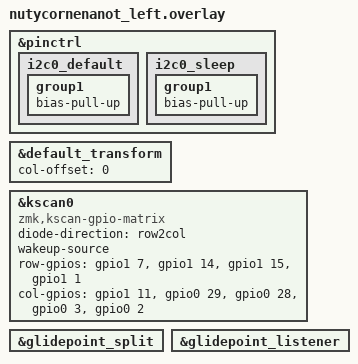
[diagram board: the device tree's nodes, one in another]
#include <input/processors.dtsi>  
#include <dt-bindings/zmk/input_transform.h>
#include <zephyr/dt-bindings/input/input-event-codes.h>

#include "nutycornenanot.dtsi"

&pinctrl {
    i2c0_default {
        group1 {
            bias-pull-up;
        };
    };
    i2c0_sleep {
        group1 {
            bias-pull-up;
        };
    };
};

&default_transform {
	col-offset = <0>;
};

&kscan0 {
    compatible = "zmk,kscan-gpio-matrix";
    diode-direction = "row2col";
    wakeup-source;

    row-gpios
        = <&gpio1  7 (GPIO_ACTIVE_HIGH)>
        //, <&gpio0 10 (GPIO_ACTIVE_HIGH)>
        //, <&gpio0  9 (GPIO_ACTIVE_HIGH)>
        , <&gpio1  14 (GPIO_ACTIVE_HIGH)>
        , <&gpio1  15 (GPIO_ACTIVE_HIGH)>
        , <&gpio1  1 (GPIO_ACTIVE_HIGH)>
        ;
    col-gpios
        = <&gpio1 11 (GPIO_ACTIVE_HIGH | GPIO_PULL_DOWN)>
        , <&gpio0 29 (GPIO_ACTIVE_HIGH | GPIO_PULL_DOWN)>
        , <&gpio0 28 (GPIO_ACTIVE_HIGH | GPIO_PULL_DOWN)>
        , <&gpio0  3 (GPIO_ACTIVE_HIGH | GPIO_PULL_DOWN)>
        , <&gpio0  2 (GPIO_ACTIVE_HIGH | GPIO_PULL_DOWN)>
        ;

};

&glidepoint_split {
    status = "ok"; 
};

&glidepoint_listener {
    status = "ok";
};


